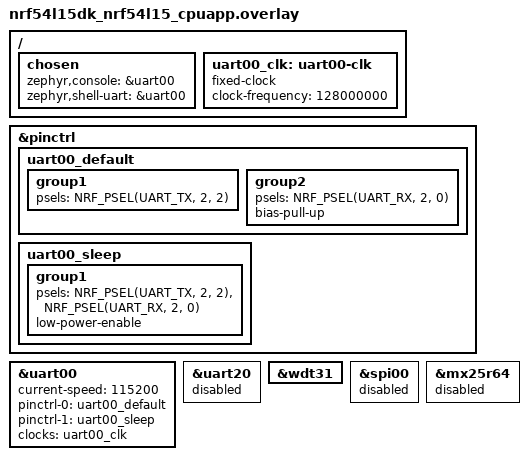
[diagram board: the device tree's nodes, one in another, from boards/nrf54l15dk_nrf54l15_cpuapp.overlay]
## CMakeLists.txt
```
cmake_minimum_required(VERSION 3.20.0)
# fck-nrf: the firmware of the nRF54L15 (U701, Minew ME54BS61) on the F*CK module.
# Its version is the VERSION file here: the application's, the one in #NRFINFO, and the one the
# MCUboot image is signed with.
# Zephyr shell + mcumgr SMP (shell transport) on uart00 -> ESP32-P4, raw 2.4 GHz RADIO commands.

find_package(Zephyr REQUIRED HINTS $ENV{ZEPHYR_BASE})
project(fck-nrf)

# The watchdog is stopped before the firmware resets itself (main.c says why): every caller of
# sys_arch_reboot(), sys_reboot() among them, goes through __wrap_sys_arch_reboot() first.
zephyr_ld_options(-Wl,--wrap=sys_arch_reboot)

target_sources(app PRIVATE
	src/main.c
	src/rf.c
)
```

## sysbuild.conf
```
# MCUboot for production: one application slot, and an image is taken by its hash alone.
#
# One slot: the module's host, the Kode, can always write the nRF again through MCUboot's serial
# recovery, so a second slot buys nothing here, and the loader that swaps two slots reads a size from
# the image's own slot before it listens to the UART. An image is written by recovery and by nothing
# else.
#
# No signature (SHA-256 of the image and no key): anyone builds and writes their own firmware. It is
# also what keeps MCUboot under the 31 KB that the nRF54L15 can protect (pm_static.yml).
#
# The partition map is pm_static.yml: NCS 3.4 does not read it unless the Partition Manager is asked
# for, and without it the image is linked for the DK's own map and does not start on the module.
SB_CONFIG_PARTITION_MANAGER=y
SB_CONFIG_BOOTLOADER_MCUBOOT=y
SB_CONFIG_MCUBOOT_MODE_SINGLE_APP=y
SB_CONFIG_BOOT_SIGNATURE_TYPE_NONE=y
```

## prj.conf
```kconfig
# fck-nrf - nRF54L15 (U701) on the F*CK module, nRF Connect SDK v3.4.2.
# One UART (uart00, P2.02/P2.00 -> ESP32-P4) carries the Zephyr shell (text commands, '#' machine
# lines) and mcumgr SMP over the shell transport (smpmgr image upload / state-write / reset).

# ---- MCUboot image (sysbuild) ------------------------------------------------------------
CONFIG_BOOTLOADER_MCUBOOT=y
# The version imgtool stamps into the image header is not set here: with a VERSION file,
# CONFIG_MCUBOOT_IMGTOOL_SIGN_VERSION defaults to its major.minor.patch+tweak. Bump VERSION on
# every release so a DFU proves something.

# ---- Shell on uart00, machine friendly ---------------------------------------------------
CONFIG_SHELL=y
CONFIG_SHELL_BACKEND_SERIAL=y
# No prompt, no echo, no colours, no VT100 cursor games: the host reads plain lines, exactly like
# fck-c5. What is typed is never echoed, and no command turns the echo on.
CONFIG_SHELL_PROMPT_UART=""
CONFIG_SHELL_ECHO_STATUS=n
CONFIG_SHELL_VT100_COLORS=n
CONFIG_SHELL_VT100_COMMANDS=n
CONFIG_SHELL_TAB=n
CONFIG_SHELL_TAB_AUTOCOMPLETION=n
CONFIG_SHELL_HISTORY=n
CONFIG_SHELL_WILDCARD=n
CONFIG_SHELL_METAKEYS=n
CONFIG_SHELL_STATS=n
# Zephyr's shell only reads the line: every line goes to the firmware's one root command, `fck`
# (main.c), which splits it and ends it with #DONE whatever it held. So none of the shell's own
# commands (clear, help, history, resize, retval, select, shell), no help printed for `-h` or for
# a wrong number of arguments, and none of its own messages.
CONFIG_SHELL_CMD_ROOT="fck"
CONFIG_SHELL_CMDS=n
CONFIG_SHELL_HELP=n
CONFIG_SHELL_MSG_CMD_NOT_FOUND=n
CONFIG_SHELL_MSG_SPECIFY_SUBCOMMAND=n
CONFIG_SHELL_LOG_BACKEND=n
CONFIG_SHELL_STACK_SIZE=4096
CONFIG_SHELL_BACKEND_SERIAL_RX_RING_BUFFER_SIZE=256
CONFIG_SHELL_ARGC_MAX=12

# Nothing else may write on the wire: no logging, no boot banners.
CONFIG_LOG=n
CONFIG_BOOT_BANNER=n
CONFIG_NCS_BOOT_BANNER=n

# ---- mcumgr SMP over the shell transport (img + os groups) ------------------------------
CONFIG_NET_BUF=y
CONFIG_ZCBOR=y
CONFIG_CRC=y
CONFIG_BASE64=y
CONFIG_MCUMGR=y
CONFIG_MCUMGR_TRANSPORT_SHELL=y
# A stray/partial SMP header must not lock the shell forever.
CONFIG_MCUMGR_TRANSPORT_SHELL_INPUT_TIMEOUT=y
CONFIG_MCUMGR_TRANSPORT_SHELL_INPUT_TIMEOUT_TIME=3000
# No image group: with one slot an image is written by MCUboot's recovery, never by the firmware.
# CONFIG_MCUMGR_GRP_IMG is not set
CONFIG_MCUMGR_GRP_OS=y
CONFIG_STREAM_FLASH=y
CONFIG_FLASH=y
CONFIG_FLASH_MAP=y
CONFIG_REBOOT=y
CONFIG_SYSTEM_WORKQUEUE_STACK_SIZE=2304
CONFIG_MCUMGR_TRANSPORT_WORKQUEUE_STACK_SIZE=4096
CONFIG_MAIN_STACK_SIZE=2176

# No external SPI-NOR on the FCK (the DK's mx25r64 is disabled in the overlay).
CONFIG_SPI_NOR=n

# ---- Watchdog: WDT31 (enabled in the overlay), fed and stopped by main.c ------------------
CONFIG_WATCHDOG=y

# ---- Radio: the app owns RADIO directly (no Bluetooth / MPSL / 802.15.4 in this build) -----
CONFIG_CLOCK_CONTROL=y
CONFIG_GPIO=y

# ---- Shell commands that reach memory or the kernel: off -----------------------------------
# Zephyr's default shell modules would let anything on the UART read and write physical memory
# (UICR.BOOTCONF, RRAMC ERASEALL, RADIO) with no image and no SMP.
CONFIG_DEVMEM_SHELL=n
CONFIG_KERNEL_SHELL=n
CONFIG_DEVICE_SHELL=n
CONFIG_DATE_SHELL=n
# The VERSION file would bring Zephyr's `app` command with it.
CONFIG_APP_VERSION_SHELL=n
```

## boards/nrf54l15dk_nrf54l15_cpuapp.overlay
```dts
/*
 * FCK module (KDFCK001 rev 1.0, Sept 2026) - nRF54L15 U701 (Minew ME54BS61) for fck-nrf.
 *
 * Host link = one UART to the ESP32-P4 (the SDK's fck_drv_nrf):
 *   nRF P2.02 (NRF.TX, pad B5) -> J401.12 -> P4 GPIO21
 *   nRF P2.00 (NRF.RX, pad A7) <- J401.14 <- P4 GPIO20
 * The Zephyr shell AND mcumgr SMP (shell transport) share it, so uart00 is both the shell UART
 * and the console. There is NO zephyr,uart-mcumgr here on purpose: CONFIG_MCUMGR_TRANSPORT_UART
 * is off (it would claim uart00's IRQ callback against the shell backend). MCUboot has its own
 * overlay (sysbuild/mcuboot.overlay) where uart00 IS zephyr,uart-mcumgr for serial recovery.
 *
 * Board fixes:
 *  - spi00 disabled: SERIAL00 @0x4a000 is spi00 OR uart00, never both.
 *  - mx25r64 disabled: the DK hangs an external flash off spi00; the FCK has none.
 *  - uart00_clk fixed-clock 128 MHz: UARTE00 PCLK is 128 MHz but BAUDRATE constants are
 *    16 MHz-based; without a `clocks` phandle 115200 becomes 921600 on the wire (8x).
 *  - uart20 disabled: DK console on P1, not wired to anything useful on the FCK.
 * P0.00 (NRF_WP_HOST, heartbeat) and P0.02 (HOST_WP_NRF) stay free: uart30, which owns
 * P0.00-P0.03 in the DK pinctrl, is disabled by default in the SoC dtsi.
 *
 * wdt31 is the firmware's watchdog (main.c). It is enabled here only, for the application:
 * MCUboot's overlay leaves it disabled, and MCUboot neither starts nor feeds it.
 */

/ {
	chosen {
		zephyr,console = &uart00;
		zephyr,shell-uart = &uart00;
		/* DK default points at uart20; SMP rides the shell here, so drop it explicitly. */
		/delete-property/ zephyr,uart-mcumgr;
	};

	uart00_clk: uart00-clk {
		compatible = "fixed-clock";
		#clock-cells = <0>;
		clock-frequency = <128000000>;
	};
};

&pinctrl {
	uart00_default: uart00_default {
		group1 {
			psels = <NRF_PSEL(UART_TX, 2, 2)>;
		};
		group2 {
			psels = <NRF_PSEL(UART_RX, 2, 0)>;
			bias-pull-up;
		};
	};

	uart00_sleep: uart00_sleep {
		group1 {
			psels = <NRF_PSEL(UART_TX, 2, 2)>,
				<NRF_PSEL(UART_RX, 2, 0)>;
			low-power-enable;
		};
	};
};

&uart00 {
	status = "okay";
	current-speed = <115200>;
	pinctrl-0 = <&uart00_default>;
	pinctrl-1 = <&uart00_sleep>;
	pinctrl-names = "default", "sleep";
	clocks = <&uart00_clk>;
};

&uart20 {
	status = "disabled";
};

&wdt31 {
	status = "okay";
};

&spi00 {
	status = "disabled";
};

&mx25r64 {
	status = "disabled";
};
```

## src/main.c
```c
/* SPDX-License-Identifier: GPL-3.0-or-later */
/*
 * fck-nrf - the firmware of the nRF54L15 (U701, Minew ME54BS61) on the F*CK module (KDFCK001
 * rev 1.0).
 *
 * Board facts (KiCad netlist, Sept 2026 board):
 *   nRF P2.02 TX -> P4 GPIO21, nRF P2.00 RX <- P4 GPIO20, 115200 8N1 (uart00, 8x baud fix in DT)
 *   P0.00 = NRF_WP_HOST  -> TCA6408A P5 (host input)  : 1 Hz heartbeat toggle (liveness)
 *   P0.02 = HOST_WP_NRF  <- TCA6408A P4 (pull-up R703): not used yet
 *   RST from TCA6408A P6 (pull-up). SWD only on TP703 SWDIO / TP704 SWCLK.
 *
 * The UART carries the Zephyr shell (no prompt, no echo, machine lines start with '#', every
 * command line ends with "#DONE <verb> rc=<n>") and mcumgr SMP over the shell transport, so text
 * commands and smpmgr DFU share the one wire. Radio commands live in rf.c.
 *
 * Zephyr's shell only reads the line. It is given one command, `fck`, set as the shell's root
 * command (CONFIG_SHELL_CMD_ROOT) and taking the rest of the line raw: so every line comes to
 * line_run() below as it was typed, and the words are split and the command is found here. That
 * way no line ends in a text of Zephyr's and without #DONE: not one with a wrong number of
 * arguments, with `-h`, with a word that is no command, or with a quote in it.
 */
#include <ctype.h>
#include <string.h>

#include <zephyr/kernel.h>
#include <zephyr/device.h>
#include <zephyr/devicetree.h>
#include <zephyr/drivers/gpio.h>
#include <zephyr/drivers/watchdog.h>
#include <zephyr/linker/linker-defs.h>
#include <zephyr/shell/shell.h>
#include <zephyr/shell/shell_uart.h>
#include <zephyr/sys/atomic.h>
#include <zephyr/sys/printk.h>
#include <hal/nrf_wdt.h>
#include <helpers/nrfx_reset_reason.h>
#include <nrfx.h>

#include "fck_nrf.h"

static uint32_t s_resetreas;

atomic_t fck_alive_mark;       /* set by fck_alive(), taken by main() */
static atomic_t s_in_command;  /* the shell's thread is inside line_run() */

uint8_t fck_node_id(void)
{
	return (uint8_t)(NRF_FICR->INFO.DEVICEID[0] & 0xFF);
}

/* ===== #NRFINFO ================================================================== */

/* Where this image was linked to run (fck_nrf.h describes the tag). The address is the
 * linker's own, so it is right whatever placed the image there. It is volatile so that the
 * compiler keeps the object and reads it, and the linker does not drop it. */
static const volatile struct fck_nrf_map_tag s_map_tag = {
	.magic = FCK_NRF_MAP_MAGIC,
	.link_address = (uint32_t)_vector_start,
};

BUILD_ASSERT(sizeof(struct fck_nrf_map_tag) == 12, "the map tag is 8 bytes and an address");

/* The line the firmware says at boot and answers `info` with. The host compares two of these
 * to know whether the chip still runs the same image and has not restarted, leaving out only
 * uptime_ms: every other value must stay the same from boot to boot's end. No counter, no state.
 * It also keeps at most 191 characters of what follows the tag. */
#define INFO_FORMAT                                                                                \
	"#NRFINFO fw=%s ver=%s devid=%08X%08X reset=0x%08X uptime_ms=%u map=0x%08X caps=%s"

BUILD_ASSERT(sizeof("fw=" FCK_NRF_FW " ver=" FCK_NRF_VERSION " devid=0123456789ABCDEF"
		    " reset=0x00000000 uptime_ms=4294967295 map=0x00000000 caps=" FCK_NRF_CAPS) <= 192,
	     "#NRFINFO is longer than the host keeps");

static void info_line(const struct shell *sh)
{
	uint32_t hi = NRF_FICR->INFO.DEVICEID[1];
	uint32_t lo = NRF_FICR->INFO.DEVICEID[0];
	uint32_t up = k_uptime_get_32();
	uint32_t map = s_map_tag.link_address;

	if (sh) {
		shell_print(sh, INFO_FORMAT, FCK_NRF_FW, FCK_NRF_VERSION, hi, lo, s_resetreas, up,
			    map, FCK_NRF_CAPS);
	} else {
		printk(INFO_FORMAT "\n", FCK_NRF_FW, FCK_NRF_VERSION, hi, lo, s_resetreas, up, map,
		       FCK_NRF_CAPS);
	}
}

/* ===== Command lines ============================================================= */

/* `rf`, its sub-command, the arguments of that, and one more word: enough to see that a line
 * has too many. */
#define WORDS_CAP (2 + FCK_ARGS_MAX + 1)

/* Cut `line` into its words, in place, at the spaces. At most `cap` words are taken. */
static int split(char *line, char **words, int cap)
{
	int n = 0;

	while (n < cap) {
		while (*line == ' ') {
			line++;
		}
		if (*line == '\0') {
			break;
		}
		words[n++] = line;
		while (*line != '\0' && *line != ' ') {
			line++;
		}
		if (*line != '\0') {
			*line++ = '\0';
		}
	}
	return n;
}

/* The #DONE verb of a line whose first word is no command: that word, as one short token. */
static void word_verb(const char *word, char *verb, size_t size)
{
	size_t i = 0;

	for (; word[i] != '\0' && i < size - 1; i++) {
		verb[i] = (isalnum((unsigned char)word[i]) || word[i] == '_') ? word[i] : '_';
	}
	verb[i] = '\0';
}

/* One command line: `first` when the shell already took the first word (NULL otherwise), and
 * the rest of the line as it was typed. Whatever the line holds, it ends with one #DONE; only a
 * line of nothing but spaces is answered with nothing, like an empty one. */
static int line_do(const struct shell *sh, const char *first, char *rest)
{
	char *words[WORDS_CAP];
	char verb[16]; /* 15 characters, what the host's line reader takes for a verb */
	int n = 0;

	if (first != NULL) {
		words[n++] = (char *)first;
	}
	n += split(rest, &words[n], WORDS_CAP - n);
	if (n == 0) {
		return 0;
	}
	if (!strcmp(words[0], "info")) {
		if (n - 1 > FCK_ARGS_MAX || fck_help_asked(n - 1, &words[1])) {
			shell_print(sh, "usage: info");
			return fck_done(sh, "info", RC_USAGE);
		}
		info_line(sh);
		return fck_done(sh, "info", RC_OK);
	}
	if (!strcmp(words[0], "rf")) {
		return rf_command(sh, n - 1, &words[1]);
	}
	word_verb(words[0], verb, sizeof(verb));
	shell_print(sh, "usage: info | rf <sub-command> ...");
	return fck_done(sh, verb, RC_USAGE);
}

/* From here to its return the shell's thread is inside a command, and the only proof that the
 * firmware is alive is the command's own fck_alive() (see "Liveness" below). */
static int line_run(const struct shell *sh, const char *first, char *rest)
{
	int rc;

	atomic_set(&s_in_command, 1);
	fck_alive();
	rc = line_do(sh, first, rest);
	fck_alive();
	atomic_set(&s_in_command, 0);
	return rc;
}

/* The three commands Zephyr's shell knows. All take the rest of the line raw, in argv[1] when
 * there is any (SHELL_OPT_ARG_RAW): the shell splits nothing and refuses nothing. `fck` is the
 * root command, so it is given every line. `info` and `rf` are the same two commands for a shell
 * that has no root command set, and are not reached while it has one. */
static char s_no_rest[1];

static int cmd_line(const struct shell *sh, size_t argc, char **argv)
{
	return line_run(sh, NULL, argc > 1 ? argv[1] : s_no_rest);
}

static int cmd_info(const struct shell *sh, size_t argc, char **argv)
{
	return line_run(sh, "info", argc > 1 ? argv[1] : s_no_rest);
}

static int cmd_rf(const struct shell *sh, size_t argc, char **argv)
{
	return line_run(sh, "rf", argc > 1 ? argv[1] : s_no_rest);
}

SHELL_CMD_ARG_REGISTER(fck, NULL, "info | rf <sub-command> ...", cmd_line, 1, SHELL_OPT_ARG_RAW);
SHELL_CMD_ARG_REGISTER(info, NULL, "#NRFINFO", cmd_info, 1, SHELL_OPT_ARG_RAW);
SHELL_CMD_ARG_REGISTER(rf, NULL, "2.4 GHz radio (nRF54L15 RADIO)", cmd_rf, 1, SHELL_OPT_ARG_RAW);

/* ===== Liveness: watchdog and heartbeat ==========================================
 *
 * A hardware watchdog, WDT31, resets a firmware that stops serving commands. Only main() feeds
 * it, twice a second, and only on proof that commands are still served:
 *
 *  - While a command runs, the proof is the command's own: fck_alive(), called from the shell's
 *    thread at the start and the end of every command and inside every loop that takes long. A
 *    command that hangs stops calling it.
 *  - While none runs, the proof is that the shell is parked waiting for a line: its lock, which
 *    it holds while it handles input, is free. The lock can be held for long with nothing wrong:
 *    the shell's thread has a low priority, and during an image upload mcumgr's thread, which
 *    writes the flash, runs ahead of it while it has the lock in hand. So a lock that stays
 *    taken counts as a hang only after SHELL_BUSY_GRACE_MS.
 *
 * Without proof main() stops feeding, and WATCHDOG_MS later the chip resets with the watchdog's
 * bit in RESETREAS (reset= in #NRFINFO). A main() that itself stops (a fatal error halts the
 * kernel; a thread above it spins) ends the same way.
 *
 * The heartbeat pin toggles on the same proof and at the same moment, so it stops at once when
 * the commands hang, seconds before the reset: it is no longer a sign that only main() runs.
 *
 * The watchdog must not be running when the firmware resets itself, as mcumgr does after an
 * upload. On the nRF54L15 a soft reset does not reset the WDT (datasheet, "Reset behavior":
 * only pin reset, the watchdog's own reset, power-on, brownout and the like do), and MCUboot as
 * NCS builds it for this SoC does not feed it (CONFIG_BOOT_WATCHDOG_FEED=n in its
 * socs/nrf54l15_cpuapp.conf): it would bite inside MCUboot's 3 s wait for serial recovery, or in
 * the middle of an image swap. So sys_arch_reboot() is wrapped (CMakeLists.txt) and stops it
 * first. A CPU lockup is the one reset left that keeps it running: MCUboot may then be reset by
 * it once, and after a watchdog reset it starts with the watchdog stopped.
 */
#define WDT_NODE            DT_NODELABEL(wdt31)
#define WATCHDOG_MS         4000
#define KEEPER_TICK_MS      500   /* one feed and one heartbeat edge: a 1 Hz square wave */
#define SHELL_BUSY_GRACE_MS 60000
#define WDT_STOP_SPINS      200000U /* reads of RUNSTATUS; the stop takes a few 32 kHz ticks */

static const struct device *const s_wdt = DEVICE_DT_GET(WDT_NODE);
static int s_wdt_channel = -1;

static int watchdog_start(void)
{
	const struct wdt_timeout_cfg cfg = {
		.window = {.min = 0, .max = WATCHDOG_MS},
		.callback = NULL,
		.flags = WDT_FLAG_RESET_SOC,
	};
	int rc;

	if (!device_is_ready(s_wdt)) {
		return -ENODEV;
	}
	rc = wdt_install_timeout(s_wdt, &cfg);
	if (rc < 0) {
		return rc;
	}
	/* It runs while the CPU sleeps (an idle hang is a sleeping CPU) and stops only while a
	 * debugger holds the CPU. */
	if (wdt_setup(s_wdt, WDT_OPT_PAUSE_HALTED_BY_DBG) < 0) {
		return -EIO;
	}
	s_wdt_channel = rc;
	return 0;
}

/* Every reboot the firmware asks for comes through here (-Wl,--wrap=sys_arch_reboot), with
 * interrupts already locked by sys_reboot(): no kernel call, only the WDT's registers. If the
 * watchdog does not stop, the reset goes ahead all the same, with a full period ahead of it. */
void __real_sys_arch_reboot(int type);

void __wrap_sys_arch_reboot(int type)
{
	NRF_WDT_Type *wdt = (NRF_WDT_Type *)DT_REG_ADDR(WDT_NODE);

	if (nrf_wdt_started_check(wdt)) {
		for (int i = 0; i < NRF_WDT_CHANNEL_NUMBER; i++) {
			nrf_wdt_reload_request_set(wdt, (nrf_wdt_rr_register_t)(NRF_WDT_RR0 + i));
		}
		nrf_wdt_task_stop_enable_set(wdt, true);
		nrf_wdt_task_trigger(wdt, NRF_WDT_TASK_STOP);
		for (uint32_t i = 0; i < WDT_STOP_SPINS && nrf_wdt_started_check(wdt); i++) {
		}
		nrf_wdt_task_stop_enable_set(wdt, false);
	}
	__real_sys_arch_reboot(type);
}

/* Whether commands are being served, as said above. Called once per tick, by main() only. */
static bool commands_alive(int64_t now)
{
	static int64_t lock_fine_at; /* when the shell's lock was last free, or a command ran */
	const struct shell *sh = shell_backend_uart_get_ptr();
	bool marked = atomic_clear(&fck_alive_mark) != 0;

	if (atomic_get(&s_in_command)) {
		/* The shell gives its lock back for as long as a command runs: the grace below
		 * starts when the command ends, however long it took. */
		lock_fine_at = now;
		return marked;
	}
	if (k_sem_take(&sh->ctx->lock_sem, K_NO_WAIT) == 0) {
		k_sem_give(&sh->ctx->lock_sem);
		lock_fine_at = now;
		return true;
	}
	return marked || (now - lock_fine_at) < SHELL_BUSY_GRACE_MS;
}

int main(void)
{
	/* Latch the reset cause first, then clear it so the next boot reports only its own. */
	s_resetreas = nrfx_reset_reason_get();
	nrfx_reset_reason_clear(s_resetreas);

	int wdt_rc = watchdog_start();
	int rc = rf_init();

	/* One machine line at boot (after MCUboot's ~3 s serial-recovery window) so the host sees
	 * the firmware come up without asking. printk goes to the same uart00 (zephyr,console). */
	info_line(NULL);
	if (wdt_rc) {
		printk("#ERR what=watchdog rc=%d\n", wdt_rc);
	}
	if (rc) {
		printk("#ERR what=rf_init rc=%d\n", rc);
	}

	/* 1 Hz heartbeat on P0.00 (pad C1 -> NRF_WP_HOST -> TCA6408A P5 input):
	 * each edge makes the expander assert ~INT, so the host has a liveness check
	 * that does not depend on the UART. */
	const struct device *p0 = DEVICE_DT_GET(DT_NODELABEL(gpio0));
	bool p0_ok = device_is_ready(p0);

	if (p0_ok) {
		gpio_pin_configure(p0, 0, GPIO_OUTPUT_INACTIVE);
	}

	int v = 0;

	while (1) {
		if (commands_alive(k_uptime_get())) {
			if (s_wdt_channel >= 0) {
				(void)wdt_feed(s_wdt, s_wdt_channel);
			}
			if (p0_ok) {
				gpio_pin_set(p0, 0, v);
				v = !v;
			}
		}
		k_sleep(K_MSEC(KEEPER_TICK_MS));
	}
	return 0;
}
```

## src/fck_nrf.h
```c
/* SPDX-License-Identifier: GPL-3.0-or-later */
/*
 * fck-nrf - shared bits between main.c (board, info, command lines, watchdog, heartbeat) and
 * rf.c (2.4 GHz radio).
 */
#ifndef FCK_NRF_H
#define FCK_NRF_H

#include <stdbool.h>
#include <stdint.h>
#include <string.h>

#include <zephyr/shell/shell.h>
#include <zephyr/sys/atomic.h>
#include <zephyr/sys/util.h>

#include <app_version.h>

#define FCK_NRF_FW "fck-nrf"

/* The version has one source, the VERSION file next to CMakeLists.txt: Zephyr turns it into
 * app_version.h, and into the version imgtool signs the MCUboot image with. `ver=` in #NRFINFO is
 * always major.minor.patch in plain digits, the form the host driver reads. */
#define FCK_NRF_VERSION                                                                            \
	STRINGIFY(APP_VERSION_MAJOR) "." STRINGIFY(APP_VERSION_MINOR) "." STRINGIFY(APP_PATCHLEVEL)

/* `caps=` in #NRFINFO: what this firmware does, for a host to decide by instead of by version.
 *   spec off power echo ping sniff scfg saddr   the `rf` sub-commands it has
 *   eu        it keeps the module's radio limits itself (fck_nrf_limits.h); nothing lifts them
 *   done      every command line ends with #DONE, whatever it held (see fck_done below)
 *   wdt       a watchdog resets a firmware that stops serving commands (reset= then says so)
 *   echoidle  the echo responder stops by itself when no ping reaches it for a while
 *   smp       firmware update by mcumgr SMP on this same UART
 * A new ability gets a new word; a word is never taken to mean something else. */
#define FCK_NRF_CAPS "spec,off,power,echo,ping,sniff,scfg,saddr,eu,done,wdt,echoidle,smp"

/* The link map tag: 12 bytes in .rodata that say where this image was linked to run, so that a
 * tool can tell it from a .signed.bin without running it.
 *   bytes 0..7   the magic: 'F' 'C' 'K' 'M' 'A' 'P' 0x00 0x01   (46 43 4B 4D 41 50 00 01)
 *   bytes 8..11  the address of the image's vector table, its first byte of code: 32 bits,
 *                little endian. 0x0000E800 with the partition map in pm_static.yml.
 * The magic appears once in an image. `map=` in #NRFINFO prints the same field. */
#define FCK_NRF_MAP_MAGIC                                                                          \
	{                                                                                          \
		'F', 'C', 'K', 'M', 'A', 'P', 0x00, 0x01                                           \
	}

struct fck_nrf_map_tag {
	uint8_t magic[8];
	uint32_t link_address;
};

/* Return codes of every command, as in fck-c5: 0 ok, 1 failed, 2 not understood. */
#define RC_OK    0
#define RC_FAIL  1
#define RC_USAGE 2

/* The most arguments a command or sub-command is given; a line with more is not understood. */
#define FCK_ARGS_MAX 8

/* Proof of life from the thread that runs the commands. A command that takes long calls this
 * at least every 250 ms; main.c feeds the watchdog and toggles the heartbeat pin only while it
 * keeps coming (or while no command runs and the shell waits for a line). It is one store: it
 * touches no peripheral and may sit beside a timing loop. */
extern atomic_t fck_alive_mark;

static inline void fck_alive(void)
{
	atomic_set(&fck_alive_mark, 1);
}

/* "#DONE <verb> rc=<n>" - the last line of every command line the firmware is sent: also of one
 * with too many words, with `-h`, or with a command or sub-command it does not have (rc=2).
 * <verb> is one token: `info`, `rf_<sub>`, `rf` when the sub-command is missing or unknown, and
 * for an unknown command its first word. Only an empty line is answered with nothing. */
static inline int fck_done(const struct shell *sh, const char *verb, int rc)
{
	fck_alive();
	shell_print(sh, "#DONE %s rc=%d", verb, rc);
	return 0; /* the shell's own return code stays 0: the protocol result is the rc= above */
}

/* `-h` or `--help` among the arguments: the line asks for the usage and runs nothing. */
static inline bool fck_help_asked(size_t argc, char **argv)
{
	for (size_t i = 0; i < argc; i++) {
		if (!strcmp(argv[i], "-h") || !strcmp(argv[i], "--help")) {
			return true;
		}
	}
	return false;
}

/* Low byte of FICR DEVICEID: node id carried in the ping/echo packets. */
uint8_t fck_node_id(void);

/* Radio module (rf.c). rf_command() runs `rf <argv[0]> <argv[1]> ...` and prints its #DONE. */
int rf_init(void);
int rf_command(const struct shell *sh, size_t argc, char **argv);

#endif /* FCK_NRF_H */
```

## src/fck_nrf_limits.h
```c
/* SPDX-License-Identifier: GPL-3.0-or-later */
/*
 * fck-nrf - the radio limits of the firmware, all of them, in this one table.
 *
 * These are the limits of the F*CK module (KDFCK001) for the EU: where it may transmit, how
 * hard, and that it never leaves an unmodulated carrier on the air. The firmware
 * has no command, no build option and no second table that lifts them: rf.c reads every one of
 * these numbers from here and holds none of its own.
 *
 * A fork that needs other limits changes them here, and only here.
 */
#ifndef FCK_NRF_LIMITS_H
#define FCK_NRF_LIMITS_H

#include <stdint.h>

struct fck_nrf_limits {
	/* Transmitting (rf ping, rf echo): the centre frequencies it may use, in MHz. */
	uint16_t tx_mhz_min;
	uint16_t tx_mhz_max;
	/* The highest TX power it sets, in dBm. A request above it is brought down to it. */
	int8_t tx_dbm_max;
	/* No unmodulated carrier: a transmitter that is still on this long after its packet
	 * should have left the air is switched off, in microseconds. (After a packet the RADIO
	 * would otherwise idle on its carrier.) */
	uint16_t tx_overrun_us;
	/* Receiving (rf spec, rf sniff): the centre frequencies it may listen on, in MHz. */
	uint16_t rx_mhz_min;
	uint16_t rx_mhz_max;
};

static const struct fck_nrf_limits fck_nrf_limits = {
	.tx_mhz_min = 2402,
	.tx_mhz_max = 2480,
	.tx_dbm_max = 6,
	.tx_overrun_us = 300,
	.rx_mhz_min = 2400,
	.rx_mhz_max = 2500,
};

#endif /* FCK_NRF_LIMITS_H */
```
